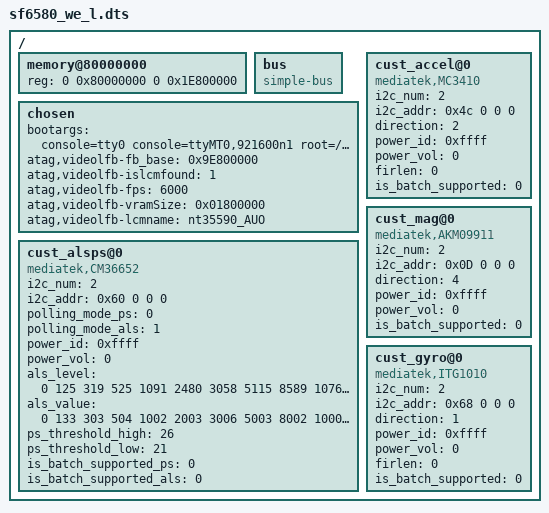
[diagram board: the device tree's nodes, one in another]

/dts-v1/;

/include/ "mt6580.dtsi"
/include/ "cust_eint.dtsi"

/ {
	memory@80000000 {
		device_type = "memory";
		reg = <0 0x80000000 0 0x1E800000>;
	};

	bus {
		compatible = "simple-bus";
		#address-cells = <1>;
		#size-cells = <1>;
		ranges = <0 0 0 0xffffffff>;
	};

    /* chosen */
    chosen {
        bootargs = "console=tty0 console=ttyMT0,921600n1 root=/dev/ram initrd=0x84000000,0x400000 loglevel=8";
		/* fpga may has no lk, we need to specify display info here */
		/* fb buffer is reserved using this dts by memory node above */
		atag,videolfb-fb_base = <0x9E800000>;
		atag,videolfb-islcmfound = <1>;
		atag,videolfb-fps= <6000>;
		atag,videolfb-vramSize= <0x01800000>;
		atag,videolfb-lcmname= "nt35590_AUO";
    };
  /*  start sensor */
		cust_accel@0 {
		compatible 				= "mediatek,MC3410";
		i2c_num 				= <2>;
		i2c_addr				= <0x4c 0 0 0>;
		direction 				= <2>;
		power_id 				= <0xffff>;
		power_vol				= <0>;
		firlen 					= <0>;
		is_batch_supported  			= <0>;
  		};
  
		cust_alsps@0 {
		compatible 				= "mediatek,CM36652";
		i2c_num 				= <2>;
		i2c_addr 				= <0x60 0 0 0>;
		polling_mode_ps			= <0>;
		polling_mode_als		= <1>;
		power_id   				= <0xffff>;
		power_vol  				= <0>; 
/* Total has 15 level*/
		als_level  				= <0 125 319 525 1091 2480 3058 5115 8589 10769 12857 17807 22091 65535 65535>;
/*  Total has 16 range*/
		als_value  				= <0 133 303 504 1002 2003 3006 5003 8002 10000 12000 16000 20000 20000 20000 20000>;
		ps_threshold_high		=  <26>;
		ps_threshold_low		=  <21>;
		is_batch_supported_ps	= <0>;
		is_batch_supported_als	= <0>;
		};
		
  		cust_mag@0 {
		compatible				= "mediatek,AKM09911";
		i2c_num 				= <2>;
		i2c_addr				= <0x0D 0 0 0>;
		direction 				= <4>;
		power_id 				= <0xffff>;
		power_vol				= <0>;
		is_batch_supported  	= <0>;
  		};
		
  		cust_gyro@0 {
		compatible 				= "mediatek,ITG1010";
		i2c_num 				= <2>;
		i2c_addr				= <0x68 0 0 0>;
		direction 				= <1>;
		power_id 				= <0xffff>;
		power_vol				= <0>;
		firlen 					= <0>;
		is_batch_supported  	= <0>;
  		};


  /* end sensor */
};
